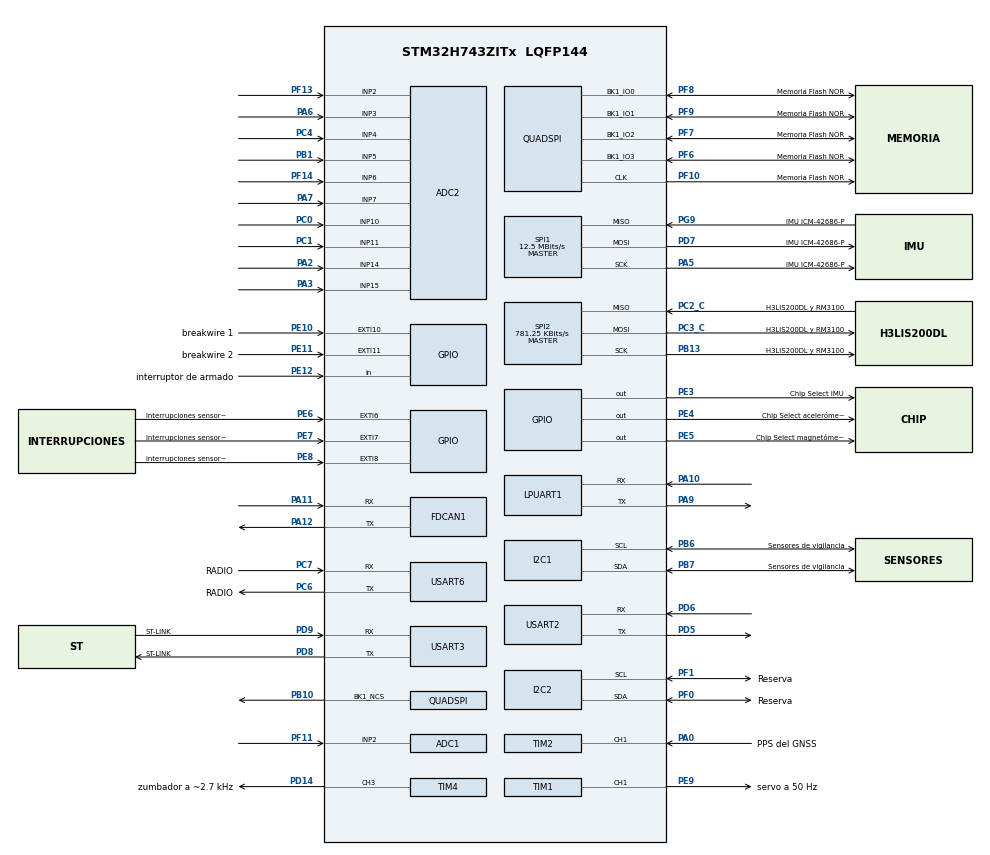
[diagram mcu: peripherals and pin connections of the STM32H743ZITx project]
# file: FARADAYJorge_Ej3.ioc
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ADC1.Channel-0\#ChannelRegularConversion=ADC_CHANNEL_2
ADC1.ClockPrescaler=ADC_CLOCK_ASYNC_DIV4
ADC1.NbrOfConversionFlag=1
ADC1.OffsetNumber-0\#ChannelRegularConversion=ADC_OFFSET_NONE
ADC1.OffsetSignedSaturation-0\#ChannelRegularConversion=DISABLE
ADC1.Rank-0\#ChannelRegularConversion=1
ADC1.SamplingTime-0\#ChannelRegularConversion=ADC_SAMPLETIME_64CYCLES_5
ADC1.master=1
ADC2.Channel-1\#ChannelRegularConversion=ADC_CHANNEL_2
ADC2.Channel-10\#ChannelRegularConversion=ADC_CHANNEL_15
ADC2.Channel-2\#ChannelRegularConversion=ADC_CHANNEL_3
ADC2.Channel-3\#ChannelRegularConversion=ADC_CHANNEL_4
ADC2.Channel-4\#ChannelRegularConversion=ADC_CHANNEL_5
ADC2.Channel-5\#ChannelRegularConversion=ADC_CHANNEL_6
ADC2.Channel-6\#ChannelRegularConversion=ADC_CHANNEL_7
ADC2.Channel-7\#ChannelRegularConversion=ADC_CHANNEL_10
ADC2.Channel-8\#ChannelRegularConversion=ADC_CHANNEL_11
ADC2.Channel-9\#ChannelRegularConversion=ADC_CHANNEL_14
ADC2.ClockPrescaler=ADC_CLOCK_ASYNC_DIV4
ADC2.NbrOfConversion=10
ADC2.NbrOfConversionFlag=1
ADC2.OffsetNumber-1\#ChannelRegularConversion=ADC_OFFSET_NONE
ADC2.OffsetNumber-10\#ChannelRegularConversion=ADC_OFFSET_NONE
ADC2.OffsetNumber-2\#ChannelRegularConversion=ADC_OFFSET_NONE
ADC2.OffsetNumber-3\#ChannelRegularConversion=ADC_OFFSET_NONE
ADC2.OffsetNumber-4\#ChannelRegularConversion=ADC_OFFSET_NONE
ADC2.OffsetNumber-5\#ChannelRegularConversion=ADC_OFFSET_NONE
ADC2.OffsetNumber-6\#ChannelRegularConversion=ADC_OFFSET_NONE
ADC2.OffsetNumber-7\#ChannelRegularConversion=ADC_OFFSET_NONE
ADC2.OffsetNumber-8\#ChannelRegularConversion=ADC_OFFSET_NONE
ADC2.OffsetNumber-9\#ChannelRegularConversion=ADC_OFFSET_NONE
ADC2.OffsetSignedSaturation-1\#ChannelRegularConversion=DISABLE
ADC2.OffsetSignedSaturation-10\#ChannelRegularConversion=DISABLE
ADC2.OffsetSignedSaturation-2\#ChannelRegularConversion=DISABLE
ADC2.OffsetSignedSaturation-3\#ChannelRegularConversion=DISABLE
ADC2.OffsetSignedSaturation-4\#ChannelRegularConversion=DISABLE
ADC2.OffsetSignedSaturation-5\#ChannelRegularConversion=DISABLE
ADC2.OffsetSignedSaturation-6\#ChannelRegularConversion=DISABLE
ADC2.OffsetSignedSaturation-7\#ChannelRegularConversion=DISABLE
ADC2.OffsetSignedSaturation-8\#ChannelRegularConversion=DISABLE
ADC2.OffsetSignedSaturation-9\#ChannelRegularConversion=DISABLE
ADC2.Rank-1\#ChannelRegularConversion=1
ADC2.Rank-10\#ChannelRegularConversion=10
ADC2.Rank-2\#ChannelRegularConversion=2
ADC2.Rank-3\#ChannelRegularConversion=3
ADC2.Rank-4\#ChannelRegularConversion=4
ADC2.Rank-5\#ChannelRegularConversion=5
ADC2.Rank-6\#ChannelRegularConversion=6
ADC2.Rank-7\#ChannelRegularConversion=7
ADC2.Rank-8\#ChannelRegularConversion=8
ADC2.Rank-9\#ChannelRegularConversion=9
ADC2.SamplingTime-1\#ChannelRegularConversion=ADC_SAMPLETIME_64CYCLES_5
ADC2.SamplingTime-10\#ChannelRegularConversion=ADC_SAMPLETIME_64CYCLES_5
ADC2.SamplingTime-2\#ChannelRegularConversion=ADC_SAMPLETIME_64CYCLES_5
ADC2.SamplingTime-3\#ChannelRegularConversion=ADC_SAMPLETIME_64CYCLES_5
ADC2.SamplingTime-4\#ChannelRegularConversion=ADC_SAMPLETIME_64CYCLES_5
ADC2.SamplingTime-5\#ChannelRegularConversion=ADC_SAMPLETIME_64CYCLES_5
ADC2.SamplingTime-6\#ChannelRegularConversion=ADC_SAMPLETIME_64CYCLES_5
ADC2.SamplingTime-7\#ChannelRegularConversion=ADC_SAMPLETIME_64CYCLES_5
ADC2.SamplingTime-8\#ChannelRegularConversion=ADC_SAMPLETIME_64CYCLES_5
ADC2.SamplingTime-9\#ChannelRegularConversion=ADC_SAMPLETIME_64CYCLES_5
ADC2.ScanConvMode=ADC_SCAN_ENABLE
CORTEX_M7.default_mode_Activation=1
FDCAN1.CalculateBaudRateNominal=500000
FDCAN1.CalculateTimeBitNominal=2000
FDCAN1.CalculateTimeQuantumNominal=100.0
FDCAN1.NominalPrescaler=5
FDCAN1.NominalSyncJumpWidth=3
FDCAN1.NominalTimeSeg1=16
FDCAN1.NominalTimeSeg2=3
FDCAN1.RxFifo0ElmtsNbr=8
FDCAN1.StdFiltersNbr=1
FDCAN1.TxFifoQueueElmtsNbr=8
FREERTOS.Events01=evFase,Dynamic,NULL
FREERTOS.Mutexes01=mtxI2C1,Dynamic,NULL,Available;mtxSPI2,Dynamic,NULL,Available
FREERTOS.Queues01=qSensores,32,muestra_t,0,Dynamic,NULL,NULL;qEstado,8,estado_t,0,Dynamic,NULL,NULL;qRegistro,64,registro_t,0,Dynamic,NULL,NULL
FREERTOS.Tasks01=Task2,24,128,Task2_init,Default,NULL,Dynamic,NULL,NULL;tIMU,48,512,fTareaIMU,Default,NULL,Dynamic,NULL,NULL;tAltaG,47,512,fTareaAltaG,Default,NULL,Dynamic,NULL,NULL;tEventos,40,512,fTareaEventos,Default,NULL,Dynamic,NULL,NULL;myTask05,32,1024,fTareaEstimacion,Default,NULL,Dynamic,NULL,NULL;tBaro,24,512,fTareaBaro,Default,NULL,Dynamic,NULL,NULL;tMag,24,512,fTareaMag,Default,NULL,Dynamic,NULL,NULL;tGNSS,24,512,fTareaGNSS,Default,NULL,Dynamic,NULL,NULL;tRegistro,16,512,fTareaRegistro,Default,NULL,Dynamic,NULL,NULL;tTelemetria,8,512,fTareaTelemetria,Default,NULL,Dynamic,NULL,NULL;tAerofreno,16,512,fTareaAerofreno,Default,NULL,Dynamic,NULL,NULL;tSalud,8,512,fTareaSalud,Default,NULL,Dynamic,NULL,NULL;tZumbador,8,512,fTareaZumbador,Default,NULL,Dynamic,NULL,NULL
FREERTOS.configCHECK_FOR_STACK_OVERFLOW=2
FREERTOS.configTOTAL_HEAP_SIZE=32768
FREERTOS.configUSE_NEWLIB_REENTRANT=1
I2C1.Timing=0x00909FCE
I2C2.Timing=0x00909FCE
Mcu.Family=STM32H7
Mcu.Name=STM32H743ZITx
Mcu.Package=LQFP144
NVIC.EXTI15_10_IRQn=true\:5\:0\:false\:false\:true\:true\:true\:true\:true
NVIC.EXTI9_5_IRQn=true\:5\:0\:true\:false\:true\:true\:true\:true\:true
NVIC.PriorityGroup=NVIC_PRIORITYGROUP_4
NVIC.TIM6_DAC_IRQn=true\:15\:0\:false\:false\:true\:false\:false\:true\:true
NVIC.TimeBase=TIM6_DAC_IRQn
NVIC.TimeBaseIP=TIM6
PA0.GPIO_Label=PPS del GNSS
PA0.Signal=S_TIM2_CH1_ETR
PA10.Mode=Asynchronous
PA10.Signal=LPUART1_RX
PA11.Mode=FDCAN_Activate
PA11.Signal=FDCAN1_RX
PA12.Mode=FDCAN_Activate
PA12.Signal=FDCAN1_TX
PA13\ (JTMS/SWDIO).Signal=DEBUG_JTMS-SWDIO
PA14\ (JTCK/SWCLK).Signal=DEBUG_JTCK-SWCLK
PA2.Signal=ADCx_INP14
PA3.Signal=ADCx_INP15
PA5.GPIO_Label=IMU ICM-42686-P
PA5.Mode=Full_Duplex_Master
PA5.Signal=SPI1_SCK
PA6.Signal=ADCx_INP3
PA7.Signal=ADCx_INP7
PA9.Mode=Asynchronous
PA9.Signal=LPUART1_TX
PB1.Signal=ADCx_INP5
PB10.Mode=Single Bank 1
PB10.Signal=QUADSPI_BK1_NCS
PB13.GPIO_Label=H3LIS200DL y RM3100
PB13.Mode=Full_Duplex_Master
PB13.Signal=SPI2_SCK
PB6.GPIO_Label=Sensores de vigilancia
PB6.Mode=I2C
PB6.Signal=I2C1_SCL
PB7.GPIO_Label=Sensores de vigilancia
PB7.Mode=I2C
PB7.Signal=I2C1_SDA
PC0.Signal=ADCx_INP10
PC1.Signal=ADCx_INP11
PC2_C.GPIO_Label=H3LIS200DL y RM3100
PC2_C.Mode=Full_Duplex_Master
PC2_C.Signal=SPI2_MISO
PC3_C.GPIO_Label=H3LIS200DL y RM3100
PC3_C.Mode=Full_Duplex_Master
PC3_C.Signal=SPI2_MOSI
PC4.Signal=ADCx_INP4
PC6.GPIO_Label=RADIO
PC6.Mode=Asynchronous
PC6.Signal=USART6_TX
PC7.GPIO_Label=RADIO
PC7.Mode=Asynchronous
PC7.Signal=USART6_RX
PD14.GPIO_Label=zumbador a ~2.7 kHz
PD14.Signal=S_TIM4_CH3
PD5.Mode=Asynchronous
PD5.Signal=USART2_TX
PD6.Mode=Asynchronous
PD6.Signal=USART2_RX
PD7.GPIO_Label=IMU ICM-42686-P
PD7.Mode=Full_Duplex_Master
PD7.Signal=SPI1_MOSI
PD8.GPIO_Label=ST-LINK
PD8.Mode=Asynchronous
PD8.Signal=USART3_TX
PD9.GPIO_Label=ST-LINK
PD9.Mode=Asynchronous
PD9.Signal=USART3_RX
PE10.GPIO_Label=breakwire 1
PE10.GPIO_ModeDefaultEXTI=GPIO_MODE_IT_RISING_FALLING
PE10.GPIO_PuPd=GPIO_PULLUP
PE10.Signal=GPXTI10
PE11.GPIO_Label=breakwire 2
PE11.GPIO_ModeDefaultEXTI=GPIO_MODE_IT_RISING_FALLING
PE11.GPIO_PuPd=GPIO_PULLUP
PE11.Signal=GPXTI11
PE12.GPIO_Label=interruptor de armado
PE12.GPIO_PuPd=GPIO_PULLUP
PE12.Signal=GPIO_Input
PE3.GPIO_Label=Chip Select IMU
PE3.PinState=GPIO_PIN_SET
PE3.Signal=GPIO_Output
PE4.GPIO_Label=Chip Select aceler\u00F3metro de altas g
PE4.PinState=GPIO_PIN_SET
PE4.Signal=GPIO_Output
PE5.GPIO_Label=Chip Select magnet\u00F3metro
PE5.PinState=GPIO_PIN_SET
PE5.Signal=GPIO_Output
PE6.GPIO_Label=interrupciones sensores
PE6.Signal=GPXTI6
PE7.GPIO_Label=interrupciones sensores
PE7.Signal=GPXTI7
PE8.GPIO_Label=interrupciones sensores
PE8.Signal=GPXTI8
PE9.GPIO_Label=servo a 50 Hz
PE9.Signal=S_TIM1_CH1
PF0.GPIO_Label=Reserva
PF0.Mode=I2C
PF0.Signal=I2C2_SDA
PF1.GPIO_Label=Reserva
PF1.Mode=I2C
PF1.Signal=I2C2_SCL
PF10.GPIO_Label=Memoria Flash NOR
PF10.Mode=Single Bank 1
PF10.Signal=QUADSPI_CLK
PF11.Mode=IN2-Single-Ended
PF11.Signal=ADC1_INP2
PF13.Mode=IN2-Single-Ended
PF13.Signal=ADC2_INP2
PF14.Mode=IN6-Single-Ended
PF14.Signal=ADC2_INP6
PF6.GPIO_Label=Memoria Flash NOR
PF6.Mode=Single Bank 1
PF6.Signal=QUADSPI_BK1_IO3
PF7.GPIO_Label=Memoria Flash NOR
PF7.Mode=Single Bank 1
PF7.Signal=QUADSPI_BK1_IO2
PF8.GPIO_Label=Memoria Flash NOR
PF8.Mode=Single Bank 1
PF8.Signal=QUADSPI_BK1_IO0
PF9.GPIO_Label=Memoria Flash NOR
PF9.Mode=Single Bank 1
PF9.Signal=QUADSPI_BK1_IO1
PG9.GPIO_Label=IMU ICM-42686-P
PG9.Mode=Full_Duplex_Master
PG9.Signal=SPI1_MISO
PH0-OSC_IN\ (PH0).Mode=HSE-External-Oscillator
PH0-OSC_IN\ (PH0).Signal=RCC_OSC_IN
PH1-OSC_OUT\ (PH1).Mode=HSE-External-Oscillator
PH1-OSC_OUT\ (PH1).Signal=RCC_OSC_OUT
ProjectManager.HeapSize=0x200
ProjectManager.StackSize=0x400
ProjectManager.TargetToolchain=STM32CubeIDE
RCC.ADCFreq_Value=75000000
RCC.APB1Freq_Value=37500000
RCC.APB2Freq_Value=37500000
RCC.APB3Freq_Value=37500000
RCC.APB4Freq_Value=75000000
RCC.CortexFreq_Value=75000000
RCC.D1PPRE=RCC_APB3_DIV2
RCC.D2PPRE1=RCC_APB1_DIV2
RCC.D2PPRE2=RCC_APB2_DIV2
RCC.DIVM1=4
RCC.DIVM2=4
RCC.DIVN1=75
RCC.DIVN2=75
RCC.DIVQ1=3
RCC.HCLKFreq_Value=75000000
RCC.HSE_VALUE=8000000
RCC.PLL1_VCI_Range=RCC_PLL1VCIRANGE_1
RCC.PLL2FRACN=0
RCC.PLL2_VCI_Range=RCC_PLL2VCIRANGE_1
RCC.PLL2_VCI_Range-AdvancedSettings=RCC_PLL2VCIRANGE_0
RCC.PLL3FRACN=0
RCC.PLL3_VCI_Range-AdvancedSettings=RCC_PLL3VCIRANGE_0
RCC.PLLFRACN=0
RCC.PLLSourceVirtual=RCC_PLLSOURCE_HSE
RCC.SYSCLKFreq_VALUE=75000000
RCC.SYSCLKSource=RCC_SYSCLKSOURCE_PLLCLK
RCC.USBFreq_Value=50000000
SH.ADCx_INP10.0=ADC2_INP10,IN10-Single-Ended
SH.ADCx_INP11.0=ADC2_INP11,IN11-Single-Ended
SH.ADCx_INP14.0=ADC2_INP14,IN14-Single-Ended
SH.ADCx_INP15.0=ADC2_INP15,IN15-Single-Ended
SH.ADCx_INP3.0=ADC2_INP3,IN3-Single-Ended
SH.ADCx_INP4.0=ADC2_INP4,IN4-Single-Ended
SH.ADCx_INP5.0=ADC2_INP5,IN5-Single-Ended
SH.ADCx_INP7.0=ADC2_INP7,IN7-Single-Ended
SH.S_TIM1_CH1.0=TIM1_CH1,PWM Generation1 CH1
SH.S_TIM2_CH1_ETR.0=TIM2_CH1,Input_Capture1_from_TI1
SH.S_TIM4_CH3.0=TIM4_CH3,PWM Generation3 CH3
SPI1.BaudRatePrescaler=SPI_BAUDRATEPRESCALER_4
SPI1.CLKPhase=SPI_PHASE_2EDGE
SPI1.CLKPolarity=SPI_POLARITY_HIGH
SPI1.CalculateBaudRate=12.5 MBits/s
SPI1.DataSize=SPI_DATASIZE_8BIT
SPI1.Direction=SPI_DIRECTION_2LINES
SPI1.MasterKeepIOState=SPI_MASTER_KEEP_IO_STATE_ENABLE
SPI1.Mode=SPI_MODE_MASTER
SPI1.VirtualType=VM_MASTER
SPI2.BaudRatePrescaler=SPI_BAUDRATEPRESCALER_64
SPI2.CLKPhase=SPI_PHASE_2EDGE
SPI2.CLKPolarity=SPI_POLARITY_HIGH
SPI2.CalculateBaudRate=781.25 KBits/s
SPI2.DataSize=SPI_DATASIZE_8BIT
SPI2.Direction=SPI_DIRECTION_2LINES
SPI2.MasterKeepIOState=SPI_MASTER_KEEP_IO_STATE_ENABLE
SPI2.Mode=SPI_MODE_MASTER
SPI2.VirtualType=VM_MASTER
TIM1.Channel-PWM\ Generation1\ CH1=TIM_CHANNEL_1
TIM1.Period=19999
TIM1.Prescaler=74
TIM1.Pulse-PWM\ Generation1\ CH1=1500
TIM2.Channel-Input_Capture1_from_TI1=TIM_CHANNEL_1
TIM2.Prescaler=74
TIM4.Channel-PWM\ Generation3\ CH3=TIM_CHANNEL_3
TIM4.Period=369
TIM4.Prescaler=74
TIM4.Pulse-PWM\ Generation3\ CH3=185
USART2.VirtualMode-Asynchronous=VM_ASYNC
USART3.VirtualMode-Asynchronous=VM_ASYNC
USART6.VirtualMode-Asynchronous=VM_ASYNC
VP_FREERTOS_VS_CMSIS_V2.Mode=CMSIS_V2
VP_MEMORYMAP_VS_MEMORYMAP.Mode=CurAppReg
VP_SYS_VS_tim6.Mode=TIM6
board=custom

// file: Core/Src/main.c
/* USER CODE BEGIN Header */
/**
  ******************************************************************************
  * @file           : main.c
  * @brief          : Main program body
  ******************************************************************************
  * @attention
  *
  * Copyright (c) 2026 STMicroelectronics.
  * All rights reserved.
  *
  * This software is licensed under terms that can be found in the LICENSE file
  * in the root directory of this software component.
  * If no LICENSE file comes with this software, it is provided AS-IS.
  *
  ******************************************************************************
  */
/* USER CODE END Header */
#include "main.h"
#include "FreeRTOS.h"
#include "cmsis_os2.h"

/* USER CODE BEGIN Includes */
#include <stdio.h>
#include "sensors/sensors.h"
/* USER CODE END Includes */

/* USER CODE BEGIN PTD */
/* Tipos de los mensajes que viajan por las colas de FreeRTOS.
 * qSensores:  tareas de sensores -> tEstimacion
 * qEstado:    tEstimacion -> tEventos, tAerofreno, tTelemetria
 * qRegistro:  todas -> tRegistro (flash NOR) */
typedef struct {
  uint32_t t_us;      /* marca de tiempo (µs, TIM2) */
  uint8_t  sensor;    /* qué sensor la ha producido */
  float    valor[3];  /* sus ejes (X, Y, Z) */
} muestra_t;

typedef struct {
  uint32_t t_us;
  float altura_m;     /* lo que estima el filtro */
  float velocidad_ms;
  float actitud[4];   /* cuaternión */
} estado_t;

typedef struct {
  uint32_t  t_us;
  muestra_t muestra;  /* lo que se guarda en la flash */
} registro_t;
/* USER CODE END PTD */

/* USER CODE BEGIN PD */
#define FLAG_IMU_DRDY  0x0001U  /* aviso de la ISR de PE6 a tIMU: «la IMU tiene dato nuevo» */
/* USER CODE END PD */

ADC_HandleTypeDef hadc1;
ADC_HandleTypeDef hadc2;

FDCAN_HandleTypeDef hfdcan1;

I2C_HandleTypeDef hi2c1;
I2C_HandleTypeDef hi2c2;

UART_HandleTypeDef hlpuart1;
UART_HandleTypeDef huart2;
UART_HandleTypeDef huart3;
UART_HandleTypeDef huart6;

QSPI_HandleTypeDef hqspi;

SPI_HandleTypeDef hspi1;
SPI_HandleTypeDef hspi2;

TIM_HandleTypeDef htim1;
TIM_HandleTypeDef htim2;
TIM_HandleTypeDef htim4;

/* Definitions for Task2 */
osThreadId_t Task2Handle;
const osThreadAttr_t Task2_attributes = {
  .name = "Task2",
  .stack_size = 128 * 4,
  .priority = (osPriority_t) osPriorityNormal,
};
/* Definitions for tIMU */
osThreadId_t tIMUHandle;
const osThreadAttr_t tIMU_attributes = {
  .name = "tIMU",
  .stack_size = 512 * 4,
  .priority = (osPriority_t) osPriorityRealtime,
};
/* Definitions for tAltaG */
osThreadId_t tAltaGHandle;
const osThreadAttr_t tAltaG_attributes = {
  .name = "tAltaG",
  .stack_size = 512 * 4,
  .priority = (osPriority_t) osPriorityHigh7,
};
/* Definitions for tEventos */
osThreadId_t tEventosHandle;
const osThreadAttr_t tEventos_attributes = {
  .name = "tEventos",
  .stack_size = 512 * 4,
  .priority = (osPriority_t) osPriorityHigh,
};
/* Definitions for myTask05 */
osThreadId_t myTask05Handle;
const osThreadAttr_t myTask05_attributes = {
  .name = "myTask05",
  .stack_size = 1024 * 4,
  .priority = (osPriority_t) osPriorityAboveNormal,
};
/* Definitions for tBaro */
osThreadId_t tBaroHandle;
const osThreadAttr_t tBaro_attributes = {
  .name = "tBaro",
  .stack_size = 512 * 4,
  .priority = (osPriority_t) osPriorityNormal,
};
/* Definitions for tMag */
osThreadId_t tMagHandle;
const osThreadAttr_t tMag_attributes = {
  .name = "tMag",
  .stack_size = 512 * 4,
  .priority = (osPriority_t) osPriorityNormal,
};
/* Definitions for tGNSS */
osThreadId_t tGNSSHandle;
const osThreadAttr_t tGNSS_attributes = {
  .name = "tGNSS",
  .stack_size = 512 * 4,
  .priority = (osPriority_t) osPriorityNormal,
};
/* Definitions for tRegistro */
osThreadId_t tRegistroHandle;
const osThreadAttr_t tRegistro_attributes = {
  .name = "tRegistro",
  .stack_size = 512 * 4,
  .priority = (osPriority_t) osPriorityBelowNormal,
};
/* Definitions for tTelemetria */
osThreadId_t tTelemetriaHandle;
const osThreadAttr_t tTelemetria_attributes = {
  .name = "tTelemetria",
  .stack_size = 512 * 4,
  .priority = (osPriority_t) osPriorityLow,
};
/* Definitions for tAerofreno */
osThreadId_t tAerofrenoHandle;
const osThreadAttr_t tAerofreno_attributes = {
  .name = "tAerofreno",
  .stack_size = 512 * 4,
  .priority = (osPriority_t) osPriorityBelowNormal,
};
/* Definitions for tSalud */
osThreadId_t tSaludHandle;
const osThreadAttr_t tSalud_attributes = {
  .name = "tSalud",
  .stack_size = 512 * 4,
  .priority = (osPriority_t) osPriorityLow,
};
/* Definitions for tZumbador */
osThreadId_t tZumbadorHandle;
const osThreadAttr_t tZumbador_attributes = {
  .name = "tZumbador",
  .stack_size = 512 * 4,
  .priority = (osPriority_t) osPriorityLow,
};
/* Definitions for qSensores */
osMessageQueueId_t qSensoresHandle;
const osMessageQueueAttr_t qSensores_attributes = {
  .name = "qSensores"
};
/* Definitions for qEstado */
osMessageQueueId_t qEstadoHandle;
const osMessageQueueAttr_t qEstado_attributes = {
  .name = "qEstado"
};
/* Definitions for qRegistro */
osMessageQueueId_t qRegistroHandle;
const osMessageQueueAttr_t qRegistro_attributes = {
  .name = "qRegistro"
};
/* Definitions for mtxI2C1 */
osMutexId_t mtxI2C1Handle;
const osMutexAttr_t mtxI2C1_attributes = {
  .name = "mtxI2C1"
};
/* Definitions for mtxSPI2 */
osMutexId_t mtxSPI2Handle;
const osMutexAttr_t mtxSPI2_attributes = {
  .name = "mtxSPI2"
};
/* Definitions for evFase */
osEventFlagsId_t evFaseHandle;
const osEventFlagsAttr_t evFase_attributes = {
  .name = "evFase"
};
/* USER CODE BEGIN PV */
static sensors_health_t   salud;   /* estado de cada sensor */
static sensors_snapshot_t datos;   /* última lectura de todos */
/* USER CODE END PV */

void SystemClock_Config(void);
void PeriphCommonClock_Config(void);
static void MPU_Config(void);
static void MX_GPIO_Init(void);
static void MX_ADC1_Init(void);
static void MX_ADC2_Init(void);
static void MX_FDCAN1_Init(void);
static void MX_I2C1_Init(void);
static void MX_I2C2_Init(void);
static void MX_LPUART1_UART_Init(void);
static void MX_USART2_UART_Init(void);
static void MX_USART3_UART_Init(void);
static void MX_USART6_UART_Init(void);
static void MX_QUADSPI_Init(void);
static void MX_SPI1_Init(void);
static void MX_SPI2_Init(void);
static void MX_TIM1_Init(void);
static void MX_TIM2_Init(void);
static void MX_TIM4_Init(void);
void Task2_init(void *argument);
void fTareaIMU(void *argument);
void fTareaAltaG(void *argument);
void fTareaEventos(void *argument);
void fTareaEstimacion(void *argument);
void fTareaBaro(void *argument);
void fTareaMag(void *argument);
void fTareaGNSS(void *argument);
void fTareaRegistro(void *argument);
void fTareaTelemetria(void *argument);
void fTareaAerofreno(void *argument);
void fTareaSalud(void *argument);
void fTareaZumbador(void *argument);

/* USER CODE BEGIN 0 */
/* printf() de newlib acaba llamando a __io_putchar() por cada carácter (ver syscalls.c).
 * Lo mandamos por USART3, que en la Nucleo sale por el USB del ST-LINK como puerto COM. */
int __io_putchar(int ch)
{
  HAL_UART_Transmit(&huart3, (uint8_t *)&ch, 1, 10);
  return ch;
}
/* USER CODE END 0 */

int main(void)
{

  /* MPU Configuration--------------------------------------------------------*/
  MPU_Config();

  /* MCU Configuration--------------------------------------------------------*/

  /* Reset of all peripherals, Initializes the Flash interface and the Systick. */
  HAL_Init();

  /* Configure the system clock */
  SystemClock_Config();

  /* Configure the peripherals common clocks */
  PeriphCommonClock_Config();

  /* Initialize all configured peripherals */
  MX_GPIO_Init();
  MX_ADC1_Init();
  MX_ADC2_Init();
  MX_FDCAN1_Init();
  MX_I2C1_Init();
  MX_I2C2_Init();
  MX_LPUART1_UART_Init();
  MX_USART2_UART_Init();
  MX_USART3_UART_Init();
  MX_USART6_UART_Init();
  MX_QUADSPI_Init();
  MX_SPI1_Init();
  MX_SPI2_Init();
  MX_TIM1_Init();
  MX_TIM2_Init();
  MX_TIM4_Init();
  /* USER CODE BEGIN 2 */
  printf("\r\nFARADAY avionica: arranque OK, SYSCLK = %lu Hz\r\n", HAL_RCC_GetSysClockFreq());

  /* Inicializar todos los sensores e informar de cuáles responden (prueba de integración). */
  sensors_init(&salud);
  printf("IMU ICM-42686-P : %s\r\n", sens_status_str(salud.imu));
  printf("Acel. H3LIS200DL: %s\r\n", sens_status_str(salud.hig));
  printf("Magn. RM3100    : %s\r\n", sens_status_str(salud.mag));
  printf("Baro. MS5607    : %s\r\n", sens_status_str(salud.baro));
  printf("INA226 vuelo    : %s\r\n", sens_status_str(salud.bat_vuelo));
  printf("INA226 recup.   : %s\r\n", sens_status_str(salud.bat_recup));
  /* USER CODE END 2 */

  /* Init scheduler */
  osKernelInitialize();
  /* Create the mutex(es) */
  /* creation of mtxI2C1 */
  mtxI2C1Handle = osMutexNew(&mtxI2C1_attributes);

  /* creation of mtxSPI2 */
  mtxSPI2Handle = osMutexNew(&mtxSPI2_attributes);

  /* Create the queue(s) */
  /* creation of qSensores */
  qSensoresHandle = osMessageQueueNew (32, sizeof(muestra_t), &qSensores_attributes);

  /* creation of qEstado */
  qEstadoHandle = osMessageQueueNew (8, sizeof(estado_t), &qEstado_attributes);

  /* creation of qRegistro */
  qRegistroHandle = osMessageQueueNew (64, sizeof(registro_t), &qRegistro_attributes);

  /* Create the thread(s) */
  /* creation of Task2 */
  Task2Handle = osThreadNew(Task2_init, NULL, &Task2_attributes);

  /* creation of tIMU */
  tIMUHandle = osThreadNew(fTareaIMU, NULL, &tIMU_attributes);

  /* creation of tAltaG */
  tAltaGHandle = osThreadNew(fTareaAltaG, NULL, &tAltaG_attributes);

  /* creation of tEventos */
  tEventosHandle = osThreadNew(fTareaEventos, NULL, &tEventos_attributes);

  /* creation of myTask05 */
  myTask05Handle = osThreadNew(fTareaEstimacion, NULL, &myTask05_attributes);

  /* creation of tBaro */
  tBaroHandle = osThreadNew(fTareaBaro, NULL, &tBaro_attributes);

  /* creation of tMag */
  tMagHandle = osThreadNew(fTareaMag, NULL, &tMag_attributes);

  /* creation of tGNSS */
  tGNSSHandle = osThreadNew(fTareaGNSS, NULL, &tGNSS_attributes);

  /* creation of tRegistro */
  tRegistroHandle = osThreadNew(fTareaRegistro, NULL, &tRegistro_attributes);

  /* creation of tTelemetria */
  tTelemetriaHandle = osThreadNew(fTareaTelemetria, NULL, &tTelemetria_attributes);

  /* creation of tAerofreno */
  tAerofrenoHandle = osThreadNew(fTareaAerofreno, NULL, &tAerofreno_attributes);

  /* creation of tSalud */
  tSaludHandle = osThreadNew(fTareaSalud, NULL, &tSalud_attributes);

  /* creation of tZumbador */
  tZumbadorHandle = osThreadNew(fTareaZumbador, NULL, &tZumbador_attributes);

  /* creation of evFase */
  evFaseHandle = osEventFlagsNew(&evFase_attributes);

  /* Start scheduler */
  osKernelStart();

  /* We should never get here as control is now taken by the scheduler */

  /* Infinite loop */
  while (1)
  {

    /* USER CODE BEGIN 3 */
    sensors_read_all(&salud, &datos);

    /* printf con %f necesita activar el soporte de float en newlib-nano: se imprimen
     * enteros escalados (mili-g, décimas de °/s, Pa) para no depender de ello. */
    printf("t=%lu ms | acc[mg] %d %d %d | gyr[0.1dps] %d %d %d | P=%ld Pa | Vbat=%d mV\r\n",
           datos.t_ms,
           (int)(datos.imu.ax_g * 1000), (int)(datos.imu.ay_g * 1000), (int)(datos.imu.az_g * 1000),
           (int)(datos.imu.gx_dps * 10), (int)(datos.imu.gy_dps * 10), (int)(datos.imu.gz_dps * 10),
           (long)datos.baro.pressure_pa, (int)(datos.bat_vuelo.bus_v * 1000));
    HAL_Delay(100);   /* 10 Hz para la consola; el bucle de vuelo real irá por tareas e interrupciones */
  }
  /* USER CODE END 3 */
}

void SystemClock_Config(void)
{
  RCC_OscInitTypeDef RCC_OscInitStruct = {0};
  RCC_ClkInitTypeDef RCC_ClkInitStruct = {0};

  /** Supply configuration update enable
  */
  HAL_PWREx_ConfigSupply(PWR_LDO_SUPPLY);

  /** Configure the main internal regulator output voltage
  */
  __HAL_PWR_VOLTAGESCALING_CONFIG(PWR_REGULATOR_VOLTAGE_SCALE3);

  while(!__HAL_PWR_GET_FLAG(PWR_FLAG_VOSRDY)) {}

  /** Initializes the RCC Oscillators according to the specified parameters
  * in the RCC_OscInitTypeDef structure.
  */
  RCC_OscInitStruct.OscillatorType = RCC_OSCILLATORTYPE_HSE;
  RCC_OscInitStruct.HSEState = RCC_HSE_ON;
  RCC_OscInitStruct.PLL.PLLState = RCC_PLL_ON;
  RCC_OscInitStruct.PLL.PLLSource = RCC_PLLSOURCE_HSE;
  RCC_OscInitStruct.PLL.PLLM = 4;
  RCC_OscInitStruct.PLL.PLLN = 75;
  RCC_OscInitStruct.PLL.PLLP = 2;
  RCC_OscInitStruct.PLL.PLLQ = 3;
  RCC_OscInitStruct.PLL.PLLR = 2;
  RCC_OscInitStruct.PLL.PLLRGE = RCC_PLL1VCIRANGE_1;
  RCC_OscInitStruct.PLL.PLLVCOSEL = RCC_PLL1VCOMEDIUM;
  RCC_OscInitStruct.PLL.PLLFRACN = 0;
  if (HAL_RCC_OscConfig(&RCC_OscInitStruct) != HAL_OK)
  {
    Error_Handler();
  }

  /** Initializes the CPU, AHB and APB buses clocks
  */
  RCC_ClkInitStruct.ClockType = RCC_CLOCKTYPE_HCLK|RCC_CLOCKTYPE_SYSCLK
                              |RCC_CLOCKTYPE_PCLK1|RCC_CLOCKTYPE_PCLK2
                              |RCC_CLOCKTYPE_D3PCLK1|RCC_CLOCKTYPE_D1PCLK1;
  RCC_ClkInitStruct.SYSCLKSource = RCC_SYSCLKSOURCE_PLLCLK;
  RCC_ClkInitStruct.SYSCLKDivider = RCC_SYSCLK_DIV1;
  RCC_ClkInitStruct.AHBCLKDivider = RCC_HCLK_DIV1;
  RCC_ClkInitStruct.APB3CLKDivider = RCC_APB3_DIV2;
  RCC_ClkInitStruct.APB1CLKDivider = RCC_APB1_DIV2;
  RCC_ClkInitStruct.APB2CLKDivider = RCC_APB2_DIV2;
  RCC_ClkInitStruct.APB4CLKDivider = RCC_APB4_DIV1;

  if (HAL_RCC_ClockConfig(&RCC_ClkInitStruct, FLASH_LATENCY_1) != HAL_OK)
  {
    Error_Handler();
  }
}

void PeriphCommonClock_Config(void)
{
  RCC_PeriphCLKInitTypeDef PeriphClkInitStruct = {0};

  /** Initializes the peripherals clock
  */
  PeriphClkInitStruct.PeriphClockSelection = RCC_PERIPHCLK_ADC;
  PeriphClkInitStruct.PLL2.PLL2M = 4;
  PeriphClkInitStruct.PLL2.PLL2N = 75;
  PeriphClkInitStruct.PLL2.PLL2P = 2;
  PeriphClkInitStruct.PLL2.PLL2Q = 2;
  PeriphClkInitStruct.PLL2.PLL2R = 2;
  PeriphClkInitStruct.PLL2.PLL2RGE = RCC_PLL2VCIRANGE_1;
  PeriphClkInitStruct.PLL2.PLL2VCOSEL = RCC_PLL2VCOMEDIUM;
  PeriphClkInitStruct.PLL2.PLL2FRACN = 0;
  PeriphClkInitStruct.AdcClockSelection = RCC_ADCCLKSOURCE_PLL2;
  if (HAL_RCCEx_PeriphCLKConfig(&PeriphClkInitStruct) != HAL_OK)
  {
    Error_Handler();
  }
}

static void MX_ADC1_Init(void)
{

  ADC_MultiModeTypeDef multimode = {0};
  ADC_ChannelConfTypeDef sConfig = {0};

  /** Common config
  */
  hadc1.Instance = ADC1;
  hadc1.Init.ClockPrescaler = ADC_CLOCK_ASYNC_DIV4;
  hadc1.Init.Resolution = ADC_RESOLUTION_16B;
  hadc1.Init.ScanConvMode = ADC_SCAN_DISABLE;
  hadc1.Init.EOCSelection = ADC_EOC_SINGLE_CONV;
  hadc1.Init.LowPowerAutoWait = DISABLE;
  hadc1.Init.ContinuousConvMode = DISABLE;
  hadc1.Init.NbrOfConversion = 1;
  hadc1.Init.DiscontinuousConvMode = DISABLE;
  hadc1.Init.ExternalTrigConv = ADC_SOFTWARE_START;
  hadc1.Init.ExternalTrigConvEdge = ADC_EXTERNALTRIGCONVEDGE_NONE;
  hadc1.Init.ConversionDataManagement = ADC_CONVERSIONDATA_DR;
  hadc1.Init.Overrun = ADC_OVR_DATA_PRESERVED;
  hadc1.Init.LeftBitShift = ADC_LEFTBITSHIFT_NONE;
  hadc1.Init.OversamplingMode = DISABLE;
  hadc1.Init.Oversampling.Ratio = 1;
  if (HAL_ADC_Init(&hadc1) != HAL_OK)
  {
    Error_Handler();
  }

  /** Configure the ADC multi-mode
  */
  multimode.Mode = ADC_MODE_INDEPENDENT;
  if (HAL_ADCEx_MultiModeConfigChannel(&hadc1, &multimode) != HAL_OK)
  {
    Error_Handler();
  }

  /** Configure Regular Channel
  */
  sConfig.Channel = ADC_CHANNEL_2;
  sConfig.Rank = ADC_REGULAR_RANK_1;
  sConfig.SamplingTime = ADC_SAMPLETIME_64CYCLES_5;
  sConfig.SingleDiff = ADC_SINGLE_ENDED;
  sConfig.OffsetNumber = ADC_OFFSET_NONE;
  sConfig.Offset = 0;
  sConfig.OffsetSignedSaturation = DISABLE;
  if (HAL_ADC_ConfigChannel(&hadc1, &sConfig) != HAL_OK)
  {
    Error_Handler();
  }

}

static void MX_ADC2_Init(void)
{

  ADC_ChannelConfTypeDef sConfig = {0};

  /** Common config
  */
  hadc2.Instance = ADC2;
  hadc2.Init.ClockPrescaler = ADC_CLOCK_ASYNC_DIV4;
  hadc2.Init.Resolution = ADC_RESOLUTION_16B;
  hadc2.Init.ScanConvMode = ADC_SCAN_ENABLE;
  hadc2.Init.EOCSelection = ADC_EOC_SINGLE_CONV;
  hadc2.Init.LowPowerAutoWait = DISABLE;
  hadc2.Init.ContinuousConvMode = DISABLE;
  hadc2.Init.NbrOfConversion = 10;
  hadc2.Init.DiscontinuousConvMode = DISABLE;
  hadc2.Init.ExternalTrigConv = ADC_SOFTWARE_START;
  hadc2.Init.ExternalTrigConvEdge = ADC_EXTERNALTRIGCONVEDGE_NONE;
  hadc2.Init.ConversionDataManagement = ADC_CONVERSIONDATA_DR;
  hadc2.Init.Overrun = ADC_OVR_DATA_PRESERVED;
  hadc2.Init.LeftBitShift = ADC_LEFTBITSHIFT_NONE;
  hadc2.Init.OversamplingMode = DISABLE;
  hadc2.Init.Oversampling.Ratio = 1;
  if (HAL_ADC_Init(&hadc2) != HAL_OK)
  {
    Error_Handler();
  }

  /** Configure Regular Channel
  */
  sConfig.Channel = ADC_CHANNEL_2;
  sConfig.Rank = ADC_REGULAR_RANK_1;
  sConfig.SamplingTime = ADC_SAMPLETIME_64CYCLES_5;
  sConfig.SingleDiff = ADC_SINGLE_ENDED;
  sConfig.OffsetNumber = ADC_OFFSET_NONE;
  sConfig.Offset = 0;
  sConfig.OffsetSignedSaturation = DISABLE;
  if (HAL_ADC_ConfigChannel(&hadc2, &sConfig) != HAL_OK)
  {
    Error_Handler();
  }

  /** Configure Regular Channel
  */
  sConfig.Channel = ADC_CHANNEL_3;
  sConfig.Rank = ADC_REGULAR_RANK_2;
  if (HAL_ADC_ConfigChannel(&hadc2, &sConfig) != HAL_OK)
  {
    Error_Handler();
  }

  /** Configure Regular Channel
  */
  sConfig.Channel = ADC_CHANNEL_4;
  sConfig.Rank = ADC_REGULAR_RANK_3;
  if (HAL_ADC_ConfigChannel(&hadc2, &sConfig) != HAL_OK)
  {
    Error_Handler();
  }

  /** Configure Regular Channel
  */
  sConfig.Channel = ADC_CHANNEL_5;
  sConfig.Rank = ADC_REGULAR_RANK_4;
  if (HAL_ADC_ConfigChannel(&hadc2, &sConfig) != HAL_OK)
  {
    Error_Handler();
  }

  /** Configure Regular Channel
  */
  sConfig.Channel = ADC_CHANNEL_6;
  sConfig.Rank = ADC_REGULAR_RANK_5;
  if (HAL_ADC_ConfigChannel(&hadc2, &sConfig) != HAL_OK)
  {
    Error_Handler();
  }

  /** Configure Regular Channel
  */
  sConfig.Channel = ADC_CHANNEL_7;
  sConfig.Rank = ADC_REGULAR_RANK_6;
  if (HAL_ADC_ConfigChannel(&hadc2, &sConfig) != HAL_OK)
  {
    Error_Handler();
  }

  /** Configure Regular Channel
  */
  sConfig.Channel = ADC_CHANNEL_10;
  sConfig.Rank = ADC_REGULAR_RANK_7;
  if (HAL_ADC_ConfigChannel(&hadc2, &sConfig) != HAL_OK)
  {
    Error_Handler();
  }

  /** Configure Regular Channel
  */
  sConfig.Channel = ADC_CHANNEL_11;
  sConfig.Rank = ADC_REGULAR_RANK_8;
  if (HAL_ADC_ConfigChannel(&hadc2, &sConfig) != HAL_OK)
  {
    Error_Handler();
  }

  /** Configure Regular Channel
  */
  sConfig.Channel = ADC_CHANNEL_14;
  sConfig.Rank = ADC_REGULAR_RANK_9;
  if (HAL_ADC_ConfigChannel(&hadc2, &sConfig) != HAL_OK)
  {
    Error_Handler();
  }

  /** Configure Regular Channel
  */
  sConfig.Channel = ADC_CHANNEL_15;
  sConfig.Rank = ADC_REGULAR_RANK_10;
  if (HAL_ADC_ConfigChannel(&hadc2, &sConfig) != HAL_OK)
  {
    Error_Handler();
  }

}

static void MX_FDCAN1_Init(void)
{

  hfdcan1.Instance = FDCAN1;
  hfdcan1.Init.FrameFormat = FDCAN_FRAME_CLASSIC;
  hfdcan1.Init.Mode = FDCAN_MODE_NORMAL;
  hfdcan1.Init.AutoRetransmission = DISABLE;
  hfdcan1.Init.TransmitPause = DISABLE;
  hfdcan1.Init.ProtocolException = DISABLE;
  hfdcan1.Init.NominalPrescaler = 5;
  hfdcan1.Init.NominalSyncJumpWidth = 3;
  hfdcan1.Init.NominalTimeSeg1 = 16;
  hfdcan1.Init.NominalTimeSeg2 = 3;
  hfdcan1.Init.DataPrescaler = 1;
  hfdcan1.Init.DataSyncJumpWidth = 1;
  hfdcan1.Init.DataTimeSeg1 = 1;
  hfdcan1.Init.DataTimeSeg2 = 1;
  hfdcan1.Init.MessageRAMOffset = 0;
  hfdcan1.Init.StdFiltersNbr = 1;
  hfdcan1.Init.ExtFiltersNbr = 0;
  hfdcan1.Init.RxFifo0ElmtsNbr = 8;
  hfdcan1.Init.RxFifo0ElmtSize = FDCAN_DATA_BYTES_8;
  hfdcan1.Init.RxFifo1ElmtsNbr = 0;
  hfdcan1.Init.RxFifo1ElmtSize = FDCAN_DATA_BYTES_8;
  hfdcan1.Init.RxBuffersNbr = 0;
  hfdcan1.Init.RxBufferSize = FDCAN_DATA_BYTES_8;
  hfdcan1.Init.TxEventsNbr = 0;
  hfdcan1.Init.TxBuffersNbr = 0;
  hfdcan1.Init.TxFifoQueueElmtsNbr = 8;
  hfdcan1.Init.TxFifoQueueMode = FDCAN_TX_FIFO_OPERATION;
  hfdcan1.Init.TxElmtSize = FDCAN_DATA_BYTES_8;
  if (HAL_FDCAN_Init(&hfdcan1) != HAL_OK)
  {
    Error_Handler();
  }

}

static void MX_I2C1_Init(void)
{

  hi2c1.Instance = I2C1;
  hi2c1.Init.Timing = 0x00909FCE;
  hi2c1.Init.OwnAddress1 = 0;
  hi2c1.Init.AddressingMode = I2C_ADDRESSINGMODE_7BIT;
  hi2c1.Init.DualAddressMode = I2C_DUALADDRESS_DISABLE;
  hi2c1.Init.OwnAddress2 = 0;
  hi2c1.Init.OwnAddress2Masks = I2C_OA2_NOMASK;
  hi2c1.Init.GeneralCallMode = I2C_GENERALCALL_DISABLE;
  hi2c1.Init.NoStretchMode = I2C_NOSTRETCH_DISABLE;
  if (HAL_I2C_Init(&hi2c1) != HAL_OK)
  {
    Error_Handler();
  }

  /** Configure Analogue filter
  */
  if (HAL_I2CEx_ConfigAnalogFilter(&hi2c1, I2C_ANALOGFILTER_ENABLE) != HAL_OK)
  {
    Error_Handler();
  }

  /** Configure Digital filter
  */
  if (HAL_I2CEx_ConfigDigitalFilter(&hi2c1, 0) != HAL_OK)
  {
    Error_Handler();
  }

}

static void MX_I2C2_Init(void)
{

  hi2c2.Instance = I2C2;
  hi2c2.Init.Timing = 0x00909FCE;
  hi2c2.Init.OwnAddress1 = 0;
  hi2c2.Init.AddressingMode = I2C_ADDRESSINGMODE_7BIT;
  hi2c2.Init.DualAddressMode = I2C_DUALADDRESS_DISABLE;
  hi2c2.Init.OwnAddress2 = 0;
  hi2c2.Init.OwnAddress2Masks = I2C_OA2_NOMASK;
  hi2c2.Init.GeneralCallMode = I2C_GENERALCALL_DISABLE;
  hi2c2.Init.NoStretchMode = I2C_NOSTRETCH_DISABLE;
  if (HAL_I2C_Init(&hi2c2) != HAL_OK)
  {
    Error_Handler();
  }

  /** Configure Analogue filter
  */
  if (HAL_I2CEx_ConfigAnalogFilter(&hi2c2, I2C_ANALOGFILTER_ENABLE) != HAL_OK)
  {
    Error_Handler();
  }

  /** Configure Digital filter
  */
  if (HAL_I2CEx_ConfigDigitalFilter(&hi2c2, 0) != HAL_OK)
  {
    Error_Handler();
  }

}

static void MX_LPUART1_UART_Init(void)
{

  hlpuart1.Instance = LPUART1;
  hlpuart1.Init.BaudRate = 209700;
  hlpuart1.Init.WordLength = UART_WORDLENGTH_8B;
  hlpuart1.Init.StopBits = UART_STOPBITS_1;
  hlpuart1.Init.Parity = UART_PARITY_NONE;
  hlpuart1.Init.Mode = UART_MODE_TX_RX;
  hlpuart1.Init.HwFlowCtl = UART_HWCONTROL_NONE;
  hlpuart1.Init.OneBitSampling = UART_ONE_BIT_SAMPLE_DISABLE;
  hlpuart1.Init.ClockPrescaler = UART_PRESCALER_DIV1;
  hlpuart1.AdvancedInit.AdvFeatureInit = UART_ADVFEATURE_NO_INIT;
  hlpuart1.FifoMode = UART_FIFOMODE_DISABLE;
  if (HAL_UART_Init(&hlpuart1) != HAL_OK)
  {
    Error_Handler();
  }
  if (HAL_UARTEx_SetTxFifoThreshold(&hlpuart1, UART_TXFIFO_THRESHOLD_1_8) != HAL_OK)
  {
    Error_Handler();
  }
  if (HAL_UARTEx_SetRxFifoThreshold(&hlpuart1, UART_RXFIFO_THRESHOLD_1_8) != HAL_OK)
  {
    Error_Handler();
  }
  if (HAL_UARTEx_DisableFifoMode(&hlpuart1) != HAL_OK)
  {
    Error_Handler();
  }

}

static void MX_USART2_UART_Init(void)
{

  huart2.Instance = USART2;
  huart2.Init.BaudRate = 115200;
  huart2.Init.WordLength = UART_WORDLENGTH_8B;
  huart2.Init.StopBits = UART_STOPBITS_1;
  huart2.Init.Parity = UART_PARITY_NONE;
  huart2.Init.Mode = UART_MODE_TX_RX;
  huart2.Init.HwFlowCtl = UART_HWCONTROL_NONE;
  huart2.Init.OverSampling = UART_OVERSAMPLING_16;
  huart2.Init.OneBitSampling = UART_ONE_BIT_SAMPLE_DISABLE;
  huart2.Init.ClockPrescaler = UART_PRESCALER_DIV1;
  huart2.AdvancedInit.AdvFeatureInit = UART_ADVFEATURE_NO_INIT;
  if (HAL_UART_Init(&huart2) != HAL_OK)
  {
    Error_Handler();
  }
  if (HAL_UARTEx_SetTxFifoThreshold(&huart2, UART_TXFIFO_THRESHOLD_1_8) != HAL_OK)
  {
    Error_Handler();
  }
  if (HAL_UARTEx_SetRxFifoThreshold(&huart2, UART_RXFIFO_THRESHOLD_1_8) != HAL_OK)
  {
    Error_Handler();
  }
  if (HAL_UARTEx_DisableFifoMode(&huart2) != HAL_OK)
  {
    Error_Handler();
  }

}

static void MX_USART3_UART_Init(void)
{

  huart3.Instance = USART3;
  huart3.Init.BaudRate = 115200;
  huart3.Init.WordLength = UART_WORDLENGTH_8B;
  huart3.Init.StopBits = UART_STOPBITS_1;
  huart3.Init.Parity = UART_PARITY_NONE;
  huart3.Init.Mode = UART_MODE_TX_RX;
  huart3.Init.HwFlowCtl = UART_HWCONTROL_NONE;
  huart3.Init.OverSampling = UART_OVERSAMPLING_16;
  huart3.Init.OneBitSampling = UART_ONE_BIT_SAMPLE_DISABLE;
  huart3.Init.ClockPrescaler = UART_PRESCALER_DIV1;
  huart3.AdvancedInit.AdvFeatureInit = UART_ADVFEATURE_NO_INIT;
  if (HAL_UART_Init(&huart3) != HAL_OK)
  {
    Error_Handler();
  }
  if (HAL_UARTEx_SetTxFifoThreshold(&huart3, UART_TXFIFO_THRESHOLD_1_8) != HAL_OK)
  {
    Error_Handler();
  }
  if (HAL_UARTEx_SetRxFifoThreshold(&huart3, UART_RXFIFO_THRESHOLD_1_8) != HAL_OK)
  {
    Error_Handler();
  }
  if (HAL_UARTEx_DisableFifoMode(&huart3) != HAL_OK)
  {
    Error_Handler();
  }

}

static void MX_USART6_UART_Init(void)
{

  huart6.Instance = USART6;
  huart6.Init.BaudRate = 115200;
  huart6.Init.WordLength = UART_WORDLENGTH_8B;
  huart6.Init.StopBits = UART_STOPBITS_1;
  huart6.Init.Parity = UART_PARITY_NONE;
  huart6.Init.Mode = UART_MODE_TX_RX;
  huart6.Init.HwFlowCtl = UART_HWCONTROL_NONE;
  huart6.Init.OverSampling = UART_OVERSAMPLING_16;
  huart6.Init.OneBitSampling = UART_ONE_BIT_SAMPLE_DISABLE;
  huart6.Init.ClockPrescaler = UART_PRESCALER_DIV1;
  huart6.AdvancedInit.AdvFeatureInit = UART_ADVFEATURE_NO_INIT;
  if (HAL_UART_Init(&huart6) != HAL_OK)
  {
    Error_Handler();
  }
  if (HAL_UARTEx_SetTxFifoThreshold(&huart6, UART_TXFIFO_THRESHOLD_1_8) != HAL_OK)
  {
    Error_Handler();
  }
  if (HAL_UARTEx_SetRxFifoThreshold(&huart6, UART_RXFIFO_THRESHOLD_1_8) != HAL_OK)
  {
    Error_Handler();
  }
  if (HAL_UARTEx_DisableFifoMode(&huart6) != HAL_OK)
  {
    Error_Handler();
  }

}

static void MX_QUADSPI_Init(void)
{

  /* QUADSPI parameter configuration*/
  hqspi.Instance = QUADSPI;
  hqspi.Init.ClockPrescaler = 255;
  hqspi.Init.FifoThreshold = 1;
  hqspi.Init.SampleShifting = QSPI_SAMPLE_SHIFTING_NONE;
  hqspi.Init.FlashSize = 1;
  hqspi.Init.ChipSelectHighTime = QSPI_CS_HIGH_TIME_1_CYCLE;
  hqspi.Init.ClockMode = QSPI_CLOCK_MODE_0;
  hqspi.Init.FlashID = QSPI_FLASH_ID_1;
  hqspi.Init.DualFlash = QSPI_DUALFLASH_DISABLE;
  if (HAL_QSPI_Init(&hqspi) != HAL_OK)
  {
    Error_Handler();
  }

}

static void MX_SPI1_Init(void)
{

  /* SPI1 parameter configuration*/
  hspi1.Instance = SPI1;
  hspi1.Init.Mode = SPI_MODE_MASTER;
  hspi1.Init.Direction = SPI_DIRECTION_2LINES;
  hspi1.Init.DataSize = SPI_DATASIZE_8BIT;
  hspi1.Init.CLKPolarity = SPI_POLARITY_HIGH;
  hspi1.Init.CLKPhase = SPI_PHASE_2EDGE;
  hspi1.Init.NSS = SPI_NSS_SOFT;
  hspi1.Init.BaudRatePrescaler = SPI_BAUDRATEPRESCALER_4;
  hspi1.Init.FirstBit = SPI_FIRSTBIT_MSB;
  hspi1.Init.TIMode = SPI_TIMODE_DISABLE;
  hspi1.Init.CRCCalculation = SPI_CRCCALCULATION_DISABLE;
  hspi1.Init.CRCPolynomial = 0x0;
  hspi1.Init.NSSPMode = SPI_NSS_PULSE_ENABLE;
  hspi1.Init.NSSPolarity = SPI_NSS_POLARITY_LOW;
  hspi1.Init.FifoThreshold = SPI_FIFO_THRESHOLD_01DATA;
  hspi1.Init.TxCRCInitializationPattern = SPI_CRC_INITIALIZATION_ALL_ZERO_PATTERN;
  hspi1.Init.RxCRCInitializationPattern = SPI_CRC_INITIALIZATION_ALL_ZERO_PATTERN;
  hspi1.Init.MasterSSIdleness = SPI_MASTER_SS_IDLENESS_00CYCLE;
  hspi1.Init.MasterInterDataIdleness = SPI_MASTER_INTERDATA_IDLENESS_00CYCLE;
  hspi1.Init.MasterReceiverAutoSusp = SPI_MASTER_RX_AUTOSUSP_DISABLE;
  hspi1.Init.MasterKeepIOState = SPI_MASTER_KEEP_IO_STATE_ENABLE;
  hspi1.Init.IOSwap = SPI_IO_SWAP_DISABLE;
  if (HAL_SPI_Init(&hspi1) != HAL_OK)
  {
    Error_Handler();
  }

}

static void MX_SPI2_Init(void)
{

  /* SPI2 parameter configuration*/
  hspi2.Instance = SPI2;
  hspi2.Init.Mode = SPI_MODE_MASTER;
  hspi2.Init.Direction = SPI_DIRECTION_2LINES;
  hspi2.Init.DataSize = SPI_DATASIZE_8BIT;
  hspi2.Init.CLKPolarity = SPI_POLARITY_HIGH;
  hspi2.Init.CLKPhase = SPI_PHASE_2EDGE;
  hspi2.Init.NSS = SPI_NSS_SOFT;
  hspi2.Init.BaudRatePrescaler = SPI_BAUDRATEPRESCALER_64;
  hspi2.Init.FirstBit = SPI_FIRSTBIT_MSB;
  hspi2.Init.TIMode = SPI_TIMODE_DISABLE;
  hspi2.Init.CRCCalculation = SPI_CRCCALCULATION_DISABLE;
  hspi2.Init.CRCPolynomial = 0x0;
  hspi2.Init.NSSPMode = SPI_NSS_PULSE_ENABLE;
  hspi2.Init.NSSPolarity = SPI_NSS_POLARITY_LOW;
  hspi2.Init.FifoThreshold = SPI_FIFO_THRESHOLD_01DATA;
  hspi2.Init.TxCRCInitializationPattern = SPI_CRC_INITIALIZATION_ALL_ZERO_PATTERN;
  hspi2.Init.RxCRCInitializationPattern = SPI_CRC_INITIALIZATION_ALL_ZERO_PATTERN;
  hspi2.Init.MasterSSIdleness = SPI_MASTER_SS_IDLENESS_00CYCLE;
  hspi2.Init.MasterInterDataIdleness = SPI_MASTER_INTERDATA_IDLENESS_00CYCLE;
  hspi2.Init.MasterReceiverAutoSusp = SPI_MASTER_RX_AUTOSUSP_DISABLE;
  hspi2.Init.MasterKeepIOState = SPI_MASTER_KEEP_IO_STATE_ENABLE;
  hspi2.Init.IOSwap = SPI_IO_SWAP_DISABLE;
  if (HAL_SPI_Init(&hspi2) != HAL_OK)
  {
    Error_Handler();
  }

}

static void MX_TIM1_Init(void)
{

  TIM_MasterConfigTypeDef sMasterConfig = {0};
  TIM_OC_InitTypeDef sConfigOC = {0};
  TIM_BreakDeadTimeConfigTypeDef sBreakDeadTimeConfig = {0};

  htim1.Instance = TIM1;
  htim1.Init.Prescaler = 74;
  htim1.Init.CounterMode = TIM_COUNTERMODE_UP;
  htim1.Init.Period = 19999;
  htim1.Init.ClockDivision = TIM_CLOCKDIVISION_DIV1;
  htim1.Init.RepetitionCounter = 0;
  htim1.Init.AutoReloadPreload = TIM_AUTORELOAD_PRELOAD_DISABLE;
  if (HAL_TIM_PWM_Init(&htim1) != HAL_OK)
  {
    Error_Handler();
  }
  sMasterConfig.MasterOutputTrigger = TIM_TRGO_RESET;
  sMasterConfig.MasterOutputTrigger2 = TIM_TRGO2_RESET;
  sMasterConfig.MasterSlaveMode = TIM_MASTERSLAVEMODE_DISABLE;
  if (HAL_TIMEx_MasterConfigSynchronization(&htim1, &sMasterConfig) != HAL_OK)
  {
    Error_Handler();
  }
  sConfigOC.OCMode = TIM_OCMODE_PWM1;
  sConfigOC.Pulse = 1500;
  sConfigOC.OCPolarity = TIM_OCPOLARITY_HIGH;
  sConfigOC.OCNPolarity = TIM_OCNPOLARITY_HIGH;
  sConfigOC.OCFastMode = TIM_OCFAST_DISABLE;
  sConfigOC.OCIdleState = TIM_OCIDLESTATE_RESET;
  sConfigOC.OCNIdleState = TIM_OCNIDLESTATE_RESET;
  if (HAL_TIM_PWM_ConfigChannel(&htim1, &sConfigOC, TIM_CHANNEL_1) != HAL_OK)
  {
    Error_Handler();
  }
  sBreakDeadTimeConfig.OffStateRunMode = TIM_OSSR_DISABLE;
  sBreakDeadTimeConfig.OffStateIDLEMode = TIM_OSSI_DISABLE;
  sBreakDeadTimeConfig.LockLevel = TIM_LOCKLEVEL_OFF;
  sBreakDeadTimeConfig.DeadTime = 0;
  sBreakDeadTimeConfig.BreakState = TIM_BREAK_DISABLE;
  sBreakDeadTimeConfig.BreakPolarity = TIM_BREAKPOLARITY_HIGH;
  sBreakDeadTimeConfig.BreakFilter = 0;
  sBreakDeadTimeConfig.Break2State = TIM_BREAK2_DISABLE;
  sBreakDeadTimeConfig.Break2Polarity = TIM_BREAK2POLARITY_HIGH;
  sBreakDeadTimeConfig.Break2Filter = 0;
  sBreakDeadTimeConfig.AutomaticOutput = TIM_AUTOMATICOUTPUT_DISABLE;
  if (HAL_TIMEx_ConfigBreakDeadTime(&htim1, &sBreakDeadTimeConfig) != HAL_OK)
  {
    Error_Handler();
  }
  HAL_TIM_MspPostInit(&htim1);

}

static void MX_TIM2_Init(void)
{

  TIM_MasterConfigTypeDef sMasterConfig = {0};
  TIM_IC_InitTypeDef sConfigIC = {0};

  htim2.Instance = TIM2;
  htim2.Init.Prescaler = 74;
  htim2.Init.CounterMode = TIM_COUNTERMODE_UP;
  htim2.Init.Period = 4294967295;
  htim2.Init.ClockDivision = TIM_CLOCKDIVISION_DIV1;
  htim2.Init.AutoReloadPreload = TIM_AUTORELOAD_PRELOAD_DISABLE;
  if (HAL_TIM_IC_Init(&htim2) != HAL_OK)
  {
    Error_Handler();
  }
  sMasterConfig.MasterOutputTrigger = TIM_TRGO_RESET;
  sMasterConfig.MasterSlaveMode = TIM_MASTERSLAVEMODE_DISABLE;
  if (HAL_TIMEx_MasterConfigSynchronization(&htim2, &sMasterConfig) != HAL_OK)
  {
    Error_Handler();
  }
  sConfigIC.ICPolarity = TIM_INPUTCHANNELPOLARITY_RISING;
  sConfigIC.ICSelection = TIM_ICSELECTION_DIRECTTI;
  sConfigIC.ICPrescaler = TIM_ICPSC_DIV1;
  sConfigIC.ICFilter = 0;
  if (HAL_TIM_IC_ConfigChannel(&htim2, &sConfigIC, TIM_CHANNEL_1) != HAL_OK)
  {
    Error_Handler();
  }

}

static void MX_TIM4_Init(void)
{

  TIM_MasterConfigTypeDef sMasterConfig = {0};
  TIM_OC_InitTypeDef sConfigOC = {0};

  htim4.Instance = TIM4;
  htim4.Init.Prescaler = 74;
  htim4.Init.CounterMode = TIM_COUNTERMODE_UP;
  htim4.Init.Period = 369;
  htim4.Init.ClockDivision = TIM_CLOCKDIVISION_DIV1;
  htim4.Init.AutoReloadPreload = TIM_AUTORELOAD_PRELOAD_DISABLE;
  if (HAL_TIM_PWM_Init(&htim4) != HAL_OK)
  {
    Error_Handler();
  }
  sMasterConfig.MasterOutputTrigger = TIM_TRGO_RESET;
  sMasterConfig.MasterSlaveMode = TIM_MASTERSLAVEMODE_DISABLE;
  if (HAL_TIMEx_MasterConfigSynchronization(&htim4, &sMasterConfig) != HAL_OK)
  {
    Error_Handler();
  }
  sConfigOC.OCMode = TIM_OCMODE_PWM1;
  sConfigOC.Pulse = 185;
  sConfigOC.OCPolarity = TIM_OCPOLARITY_HIGH;
  sConfigOC.OCFastMode = TIM_OCFAST_DISABLE;
  if (HAL_TIM_PWM_ConfigChannel(&htim4, &sConfigOC, TIM_CHANNEL_3) != HAL_OK)
  {
    Error_Handler();
  }
  HAL_TIM_MspPostInit(&htim4);

}

static void MX_GPIO_Init(void)
{
  GPIO_InitTypeDef GPIO_InitStruct = {0};

  /* GPIO Ports Clock Enable */
  __HAL_RCC_GPIOE_CLK_ENABLE();
  __HAL_RCC_GPIOF_CLK_ENABLE();
  __HAL_RCC_GPIOH_CLK_ENABLE();
  __HAL_RCC_GPIOC_CLK_ENABLE();
  __HAL_RCC_GPIOA_CLK_ENABLE();
  __HAL_RCC_GPIOB_CLK_ENABLE();
  __HAL_RCC_GPIOD_CLK_ENABLE();
  __HAL_RCC_GPIOG_CLK_ENABLE();

  /*Configure GPIO pin Output Level */
  HAL_GPIO_WritePin(GPIOE, Chip_Select_IMU_Pin|Chip_Select_aceler_metro_de_altas_g_Pin|Chip_Select_magnet_metro_Pin, GPIO_PIN_SET);

  /*Configure GPIO pins : Chip_Select_IMU_Pin Chip_Select_aceler_metro_de_altas_g_Pin Chip_Select_magnet_metro_Pin */
  GPIO_InitStruct.Pin = Chip_Select_IMU_Pin|Chip_Select_aceler_metro_de_altas_g_Pin|Chip_Select_magnet_metro_Pin;
  GPIO_InitStruct.Mode = GPIO_MODE_OUTPUT_PP;
  GPIO_InitStruct.Pull = GPIO_NOPULL;
  GPIO_InitStruct.Speed = GPIO_SPEED_FREQ_LOW;
  HAL_GPIO_Init(GPIOE, &GPIO_InitStruct);

  /*Configure GPIO pins : interrupciones_sensores_Pin interrupciones_sensoresE7_Pin interrupciones_sensoresE8_Pin */
  GPIO_InitStruct.Pin = interrupciones_sensores_Pin|interrupciones_sensoresE7_Pin|interrupciones_sensoresE8_Pin;
  GPIO_InitStruct.Mode = GPIO_MODE_IT_RISING;
  GPIO_InitStruct.Pull = GPIO_NOPULL;
  HAL_GPIO_Init(GPIOE, &GPIO_InitStruct);

  /*Configure GPIO pins : breakwire_1_Pin breakwire_2_Pin */
  GPIO_InitStruct.Pin = breakwire_1_Pin|breakwire_2_Pin;
  GPIO_InitStruct.Mode = GPIO_MODE_IT_RISING_FALLING;
  GPIO_InitStruct.Pull = GPIO_PULLUP;
  HAL_GPIO_Init(GPIOE, &GPIO_InitStruct);

  /*Configure GPIO pin : interruptor_de_armado_Pin */
  GPIO_InitStruct.Pin = interruptor_de_armado_Pin;
  GPIO_InitStruct.Mode = GPIO_MODE_INPUT;
  GPIO_InitStruct.Pull = GPIO_PULLUP;
  HAL_GPIO_Init(interruptor_de_armado_GPIO_Port, &GPIO_InitStruct);

  /* EXTI interrupt init*/
  HAL_NVIC_SetPriority(interrupciones_sensores_EXTI_IRQn, 5, 0);
  HAL_NVIC_EnableIRQ(interrupciones_sensores_EXTI_IRQn);

  HAL_NVIC_SetPriority(breakwire_1_EXTI_IRQn, 5, 0);
  HAL_NVIC_EnableIRQ(breakwire_1_EXTI_IRQn);

}

/* USER CODE BEGIN 4 */
/* La ISR de las EXTI. Regla: una interrupción no hace trabajo, solo avisa.
 * La lectura SPI la hace tIMU, que es una tarea y puede esperar al bus. */
void HAL_GPIO_EXTI_Callback(uint16_t GPIO_Pin)
{
  if (GPIO_Pin == interrupciones_sensores_Pin)        /* PE6: dato listo de la IMU */
  {
    osThreadFlagsSet(tIMUHandle, FLAG_IMU_DRDY);
  }
}

/* USER CODE END 4 */

void Task2_init(void *argument)
{
  for(;;)
  {
    osDelay(1);
  }
}

void fTareaIMU(void *argument)
{
  /* USER CODE BEGIN fTareaIMU */
	 /*
	   * QUÉ HACE: lee la IMU ICM-42686-P (SPI1) a 1 kHz y publica la muestra.
	   * CÓMO SE DESPIERTA: no hace polling. La IMU genera una interrupción de
	   *   «dato listo» en PE6; la ISR (HAL_GPIO_EXTI_Callback) solo hace
	   *   osThreadFlagsSet(tIMUHandle, FLAG_IMU_DRDY) y sale.
	   * RECIBE: el flag FLAG_IMU_DRDY.
	   * ENVÍA: una muestra_t con marca de tiempo (TIM2, µs) a qSensores (para
	   *   el filtro) y a qRegistro (para la flash).
	   * PRIORIDAD: osPriorityRealtime, el plazo más corto del sistema (1 ms).
	   * SI FALLA: si en 5 ms no llega el flag, marca la IMU como no disponible
	   *   en la salud del sistema y sigue (el filtro usa el resto de sensores).
	   */
  /* Infinite loop */
	  muestra_t m;
	  icm42686_data_t imu;
	  for (;;)
	  {
	    /* Duerme hasta que la ISR avise (máximo 5 ms) */
	    uint32_t f = osThreadFlagsWait(FLAG_IMU_DRDY, osFlagsWaitAny, 5);
	    if (f & osFlagsError)
	    {
	      continue;  /* timeout: la IMU no ha avisado (avisar a tSalud) */
	    }
	    if (icm42686_read(&imu) == SENS_OK)
	    {
	      m.t_us     = osKernelGetTickCount() * 1000U;   /* ms -> µs (luego, con TIM2) */
	      m.sensor   = 0;                                /* 0 = IMU */
	      m.valor[0] = imu.ax_g;
	      m.valor[1] = imu.ay_g;
	      m.valor[2] = imu.az_g;
	      osMessageQueuePut(qSensoresHandle, &m, 0, 0);  /* 0 = no esperar si la cola está llena */
	    }
	  }
  /* USER CODE END fTareaIMU */
}

void fTareaAltaG(void *argument)
{
  /* USER CODE BEGIN fTareaAltaG */
	  /*
	   * QUÉ HACE: lee el acelerómetro de alta g H3LIS200DL (SPI2, ±200 g).
	   * FRECUENCIA: 1 kHz durante la propulsión; 100 Hz cuando evFase marca el apagado del motor.
	   * COMUNICACIÓN: toma el mutex mtxSPI2 (comparte bus con el magnetómetro) y envía
	   *   muestra_t a qSensores y qRegistro.
	   * PRIORIDAD: High7. Es la única medida válida en el empuje, cuando la IMU satura.
	   * SI FALLA: sin este sensor, el filtro usa la IMU, aunque esté saturada en el empuje.
	   */
  /* Infinite loop */
  for(;;)
  {
    osDelay(1);
  }
  /* USER CODE END fTareaAltaG */
}

void fTareaEventos(void *argument)
{
  /* USER CODE BEGIN fTareaEventos */
	  /*
	   * QUÉ HACE: máquina de estados del vuelo: rampa, despegue, apagado, apogeo,
	   *   drogue, principal y aterrizaje. Dispara las cargas de recuperación.
	   * FRECUENCIA: 100 Hz.
	   * RECIBE: el estado estimado de qEstado (altura, velocidad, aceleración).
	   * ENVÍA: los bits de fase a evFase, que leen todas las tareas para cambiar su comportamiento.
	   * PRIORIDAD: High. Si el apogeo se detecta tarde, el paracaídas sale tarde y se pierde el cohete.
	   */
  /* Infinite loop */
  for(;;)
  {
    osDelay(1);
  }
  /* USER CODE END fTareaEventos */
}

void fTareaEstimacion(void *argument)
{
  /* USER CODE BEGIN fTareaEstimacion */
	  /*
	   * QUÉ HACE: filtro de Kalman extendido. Fusiona IMU, alta g, barómetro,
	   *   magnetómetro y GNSS para estimar posición, velocidad y actitud.
	   * FRECUENCIA: 200 Hz.
	   * RECIBE: muestra_t de qSensores.
	   * ENVÍA: estado_t a qEstado (para eventos, aerofreno y telemetría).
	   * PRIORIDAD: AboveNormal. Es crítica, pero es la que más CPU consume (~16 Mciclos/s):
	   *   por encima robaría tiempo a la IMU y a los eventos.
	   * NOTA: si un sensor satura, su muestra se descarta. Un valor saturado no tiene ruido
	   *   gaussiano y rompe el modelo estadístico del filtro.
	   */
  /* Infinite loop */
	  muestra_t m;
	  estado_t  e = {0};
	  for (;;)
	  {
	    /* Espera la siguiente muestra (de cualquier sensor) */
	    if (osMessageQueueGet(qSensoresHandle, &m, NULL, 10) == osOK)
	    {
	      /* Aquí iría el paso del filtro de Kalman: predicción con la IMU,
	       * corrección con barómetro, magnetómetro y GNSS. */
	      e.t_us = m.t_us;
	      osMessageQueuePut(qEstadoHandle, &e, 0, 0);   /* publica la estimación */
	    }
	  }
  /* USER CODE END fTareaEstimacion */
}

void fTareaBaro(void *argument)
{
  /* USER CODE BEGIN fTareaBaro */
	  /*
	   * QUÉ HACE: lee el barómetro MS5607 (I2C1) y calcula la presión compensada.
	   * FRECUENCIA: 50 Hz, como máquina de estados: pide la conversión, duerme 10 ms con
	   *   osDelay y lee. Nunca bloquea la CPU.
	   * COMUNICACIÓN: toma el mutex mtxI2C1 (comparte bus con los INA226) y envía
	   *   muestra_t a qSensores y qRegistro.
	   * PRIORIDAD: Normal. Es lento y tolera retrasos; deja de servir por encima de ~30 km.
	   */
  /* Infinite loop */
	  muestra_t m;
	  ms5607_data_t baro;
	  uint32_t siguiente = osKernelGetTickCount();
	  for (;;)
	  {
	    /* El I2C1 lo comparte con tSalud (INA226): solo uno a la vez */
	    if (osMutexAcquire(mtxI2C1Handle, 10) == osOK)
	    {
	      sens_status_t st = ms5607_read(&baro);
	      osMutexRelease(mtxI2C1Handle);              /* soltarlo SIEMPRE */
	      if (st == SENS_OK)
	      {
	        m.t_us     = osKernelGetTickCount() * 1000U;
	        m.sensor   = 3;                            /* 3 = barómetro */
	        m.valor[0] = baro.pressure_pa;
	        m.valor[1] = baro.temp_c;
	        m.valor[2] = 0;
	        osMessageQueuePut(qSensoresHandle, &m, 0, 0);
	      }
	    }
	    siguiente += 20;                               /* 20 ms = 50 Hz */
	    osDelayUntil(siguiente);
	  }
  /* USER CODE END fTareaBaro */
}

void fTareaMag(void *argument)
{
  /* USER CODE BEGIN fTareaMag */
	  /*
	   * QUÉ HACE: lee el magnetómetro RM3100 (SPI2): referencia de rumbo (guiñada).
	   * FRECUENCIA: 100 Hz.
	   * COMUNICACIÓN: toma el mutex mtxSPI2 (comparte bus con el acelerómetro de alta g)
	   *   y envía muestra_t a qSensores y qRegistro.
	   * PRIORIDAD: Normal. Corrige una deriva lenta, así que tolera retrasos.
	   */
  /* Infinite loop */
  for(;;)
  {
    osDelay(1);
  }
  /* USER CODE END fTareaMag */
}

void fTareaGNSS(void *argument)
{
  /* USER CODE BEGIN fTareaGNSS */
	  /*
	   * QUÉ HACE: recibe y decodifica las tramas del GNSS u-blox (USART2, DMA).
	   * FRECUENCIA: 10 Hz.
	   * ENVÍA: posición y velocidad a qSensores, cuando hay fix.
	   * PRIORIDAD: Normal. Es una ayuda intermitente: se bloquea en el ascenso por COCOM.
	   */
  /* Infinite loop */
  for(;;)
  {
    osDelay(1);
  }
  /* USER CODE END fTareaGNSS */
}

void fTareaRegistro(void *argument)
{
  /* USER CODE BEGIN fTareaRegistro */
	  /*
	   * QUÉ HACE: vacía qRegistro y escribe los datos en la flash NOR (QSPI) por bloques.
	   * FRECUENCIA: 200 Hz.
	   * RECIBE: registro_t de qRegistro (64 elementos, para absorber la lentitud de la flash).
	   * PRIORIDAD: BelowNormal. La cola absorbe los retrasos, y escribir en flash es lento:
	   *   no puede ir por encima de las tareas de control.
	   */
  /* Infinite loop */
  for(;;)
  {
    osDelay(1);
  }
  /* USER CODE END fTareaRegistro */
}

void fTareaTelemetria(void *argument)
{
  /* USER CODE BEGIN fTareaTelemetria */
	  /*
	   * QUÉ HACE: envía el estado a tierra por la radio (USART6, 868 MHz).
	   * FRECUENCIA: 10 Hz.
	   * RECIBE: estado_t de qEstado y los bits de evFase.
	   * PRIORIDAD: Low. Solo sirve en tierra; nada en vuelo depende de ella.
	   */
  /* Infinite loop */
  for(;;)
  {
    osDelay(1);
  }
  /* USER CODE END fTareaTelemetria */
}

void fTareaAerofreno(void *argument)
{
  /* USER CODE BEGIN fTareaAerofreno */
	  /*
	   * QUÉ HACE: calcula la posición del aerofreno para controlar el apogeo y la envía
	   *   por CAN (FDCAN1) al nodo de la otra bahía.
	   * FRECUENCIA: 50 Hz.
	   * RECIBE: estado_t de qEstado. Solo actúa cuando evFase marca el apagado del motor.
	   * PRIORIDAD: BelowNormal. Necesita la estimación, pero unos ms de retraso no son críticos.
	   */
  /* Infinite loop */
  for(;;)
  {
    osDelay(1);
  }
  /* USER CODE END fTareaAerofreno */
}

void fTareaSalud(void *argument)
{
  /* USER CODE BEGIN fTareaSalud */
	  /*
	   * QUÉ HACE: vigila la batería (INA226 por I2C1), las temperaturas y el estado de
	   *   cada sensor. Refresca el watchdog (IWDG) solo si todas las tareas críticas
	   *   han dado señal de vida.
	   * FRECUENCIA: 1 Hz.
	   * COMUNICACIÓN: toma el mutex mtxI2C1 (comparte bus con el barómetro).
	   * PRIORIDAD: Low. Es lenta, pero si una tarea crítica se cuelga, el watchdog reinicia el micro.
	   */
  /* Infinite loop */
  for(;;)
  {
    osDelay(1);
  }
  /* USER CODE END fTareaSalud */
}

void fTareaZumbador(void *argument)
{
  /* USER CODE BEGIN fTareaZumbador */
	  /*
	   * QUÉ HACE: emite pitidos (TIM4 PWM, ~2,7 kHz) según la fase: armado en rampa,
	   *   errores y localización tras aterrizar.
	   * FRECUENCIA: según el evento (lee evFase).
	   * PRIORIDAD: Low. Es la menos importante en vuelo.
	   */
  /* Infinite loop */
  for(;;)
  {
    osDelay(1);
  }
  /* USER CODE END fTareaZumbador */
}

 /* MPU Configuration */

void MPU_Config(void)
{
  MPU_Region_InitTypeDef MPU_InitStruct = {0};

  /* Disables the MPU */
  HAL_MPU_Disable();

  /** Initializes and configures the Region and the memory to be protected
  */
  MPU_InitStruct.Enable = MPU_REGION_ENABLE;
  MPU_InitStruct.Number = MPU_REGION_NUMBER0;
  MPU_InitStruct.BaseAddress = 0x0;
  MPU_InitStruct.Size = MPU_REGION_SIZE_4GB;
  MPU_InitStruct.SubRegionDisable = 0x87;
  MPU_InitStruct.TypeExtField = MPU_TEX_LEVEL0;
  MPU_InitStruct.AccessPermission = MPU_REGION_NO_ACCESS;
  MPU_InitStruct.DisableExec = MPU_INSTRUCTION_ACCESS_DISABLE;
  MPU_InitStruct.IsShareable = MPU_ACCESS_SHAREABLE;
  MPU_InitStruct.IsCacheable = MPU_ACCESS_NOT_CACHEABLE;
  MPU_InitStruct.IsBufferable = MPU_ACCESS_NOT_BUFFERABLE;

  HAL_MPU_ConfigRegion(&MPU_InitStruct);
  /* Enables the MPU */
  HAL_MPU_Enable(MPU_PRIVILEGED_DEFAULT);

}

void HAL_TIM_PeriodElapsedCallback(TIM_HandleTypeDef *htim)
{
  if (htim->Instance == TIM6)
  {
    HAL_IncTick();
  }
}

void Error_Handler(void)
{
  __disable_irq();
  while (1)
  {
  }
}
